# MCF5441x register map
Vendor: NXP; File version: 1.0
Registers are 32-bit, read-write, reset 0x0 unless marked. A register's access mark holds for its fields unless they carry their own. Offsets are from the block's base; [hi:lo] are bit positions; {n}, {i} and the like mark numbered series.

## ADC
Base 0xFC094000
0x00 CR1 16-bit reset 0x5005
0x02 CR2 16-bit reset 0x5080
0x04 ZCCR 16-bit
0x06 LST1 16-bit reset 0x3210
0x08 LST2 16-bit reset 0x7654
0x0A SDIS 16-bit
0x0C SR 16-bit
0x0E LSR 16-bit
0x10 ZCSR 16-bit
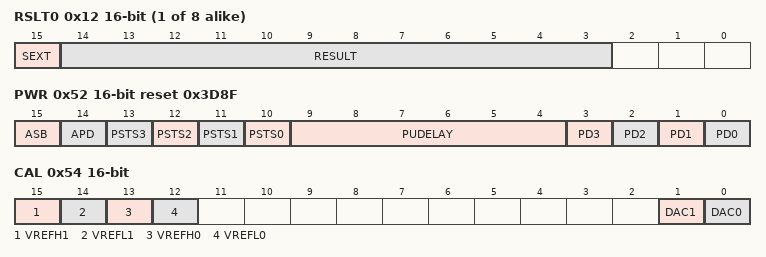
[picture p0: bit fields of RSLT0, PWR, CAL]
{0x12+2i} RSLT{i} 16-bit (i=0..7)
  [15] SEXT read-has-side-effects
    0=POSITIVE_RESULT; 1=NEGATIVE_RESULT
  [14:3] RESULT read-has-side-effects
{0x22+2i} LLMT{i} 16-bit (i=0..7)
{0x32+2i} HLMT{i} 16-bit reset 0x7FF8 (i=0..7)
{0x42+2i} OFS{i} 16-bit (i=0..7)
  [14:3] OFFSET
0x52 PWR 16-bit reset 0x3D8F
  [15] ASB
    0=DISABLED; 1=ENABLED
  [14] APD
  [n+10] PSTS{n} (n=0..3)
  [9:4] PUDELAY
  [n] PD{n} (n=0..3)
0x54 CAL 16-bit
  [15] VREFH1
    0=INTERNAL_VDDA; 1=ADC_IN4
  [14] VREFL1
    0=INTERNAL_VSSA; 1=ADC_IN5
  [13] VREFH0
    0=INTERNAL_VDDA; 1=ADC_IN0
  [12] VREFL0
    0=INTERNAL_VSSA; 1=ADC_IN1
  [1] DAC1
  [0] DAC0
0x56 PWR2 16-bit reset 0x5
0x58 DIV 16-bit reset 0x505
0x5A ASDIV 16-bit reset 0x137

## CCM
Base 0xEC090000
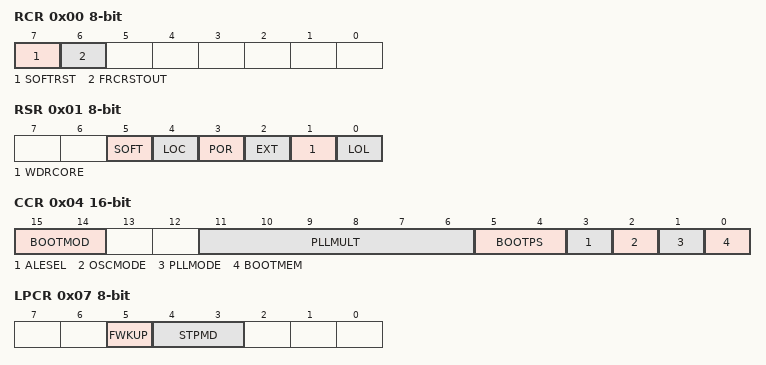
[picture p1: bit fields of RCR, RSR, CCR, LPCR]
0x00 RCR 8-bit
  [7] SOFTRST
    0=NO_SOFTWARE_RESET_REQUEST; 1=SOFTWARE_RESET_REQUEST
  [6] FRCRSTOUT
    0=NEGATE_RSTOUT; 1=ASSERT_RSTOUT
0x01 RSR 8-bit ro reset not defined
  [5] SOFT, [4] LOC, [3] POR, [2] EXT, [1] WDRCORE, [0] LOL
0x04 CCR 16-bit ro reset not defined
  [15:14] BOOTMOD
  [11:6] PLLMULT
  [5:4] BOOTPS
  [3] ALESEL
    0=TS; 1=ALE
  [2] OSCMODE
    0=CRYSTAL_OSCILLATOR_MODE; 1=OSCILLATOR_BYPASS_MODE
  [1] PLLMODE
    0=DISABLED; 1=ENABLED
  [0] BOOTMEM
    0=NAND_FLASH; 1=FLEXBUS
0x07 LPCR 8-bit
  [5] FWKUP, [4:3] STPMD
0x08 RCON 16-bit ro reset 0x1259
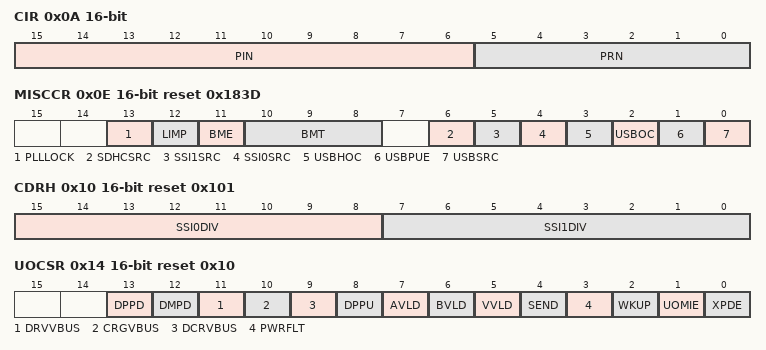
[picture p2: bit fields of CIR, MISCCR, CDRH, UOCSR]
0x0A CIR 16-bit ro reset not defined
  [15:6] PIN, [5:0] PRN
0x0E MISCCR 16-bit reset 0x183D
  [13] PLLLOCK
    0=NOT_LOCKED; 1=LOCKED
  [12] LIMP
  [11] BME
  [10:8] BMT
  [6] SDHCSRC
    0=OSCILLATOR_OUTPUT; 1=PLL_DIVIDER_OUTPUT
  [5] SSI1SRC
    0=SSI_CLKIN_PIN; 1=PLL_OUTPUT
  [4] SSI0SRC
    0=SSI_CLKIN_PIN; 1=PLL_OUTPUT
  [3] USBHOC
    0=LOW; 1=HIGH
  [2] USBOC
    0=LOW; 1=HIGH
  [1] USBPUE
  [0] USBSRC
0x10 CDRH 16-bit reset 0x101
  [15:8] SSI0DIV, [7:0] SSI1DIV
0x12 CDRL 16-bit
  [11:8] LPDIV
0x14 UOCSR 16-bit reset 0x10
  [13] DPPD read-has-side-effects
    0=DISABLED; 1=ENABLED
  [12] DMPD read-has-side-effects
    0=DISABLED; 1=ENABLED
  [11] DRVVBUS read-has-side-effects
  [10] CRGVBUS read-has-side-effects
  [9] DCRVBUS read-has-side-effects
  [8] DPPU read-has-side-effects
  [7] AVLD read-has-side-effects
  [6] BVLD read-has-side-effects
  [5] VVLD read-has-side-effects
  [4] SEND read-has-side-effects
  [3] PWRFLT read-has-side-effects
  [2] WKUP read-has-side-effects
  [1] UOMIE read-has-side-effects
    0=DISABLED; 1=ENABLED
  [0] XPDE read-has-side-effects
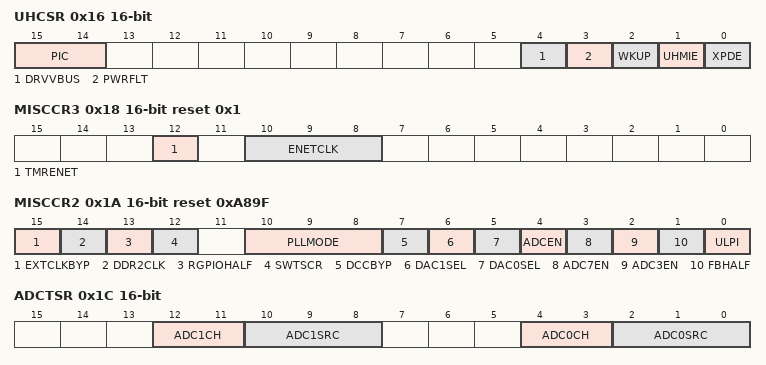
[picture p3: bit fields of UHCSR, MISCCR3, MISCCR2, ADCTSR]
0x16 UHCSR 16-bit
  [15:14] PIC read-has-side-effects
  [4] DRVVBUS read-has-side-effects
  [3] PWRFLT read-has-side-effects
  [2] WKUP read-has-side-effects
  [1] UHMIE read-has-side-effects
    0=DISABLED; 1=ENABLED
  [0] XPDE read-has-side-effects
0x18 MISCCR3 16-bit reset 0x1
  [12] TMRENET
    0=MAC0_1588_TIMEBASE_COUNTER; 1=MAC1_1588_TIMEBASE_COUNTER
  [10:8] ENETCLK
0x1A MISCCR2 16-bit reset 0xA89F
  [15] EXTCLKBYP
  [14] DDR2CLK
  [13] RGPIOHALF
  [12] SWTSCR
  [10:8] PLLMODE
  [7] DCCBYP
  [6] DAC1SEL
  [5] DAC0SEL
  [4] ADCEN
    0=DISABLED; 1=ENABLED
  [3] ADC7EN
    0=DISABLED; 1=ENABLED
  [2] ADC3EN
    0=DISABLED; 1=ENABLED
  [1] FBHALF
    0=FLEXBUS_RUNS_AT_FSYS_2; 1=FLEXBUS_RUNS_AT_FSYS_4
  [0] ULPI
0x1C ADCTSR 16-bit
  [12:11] ADC1CH, [10:8] ADC1SRC, [4:3] ADC0CH, [2:0] ADC0SRC
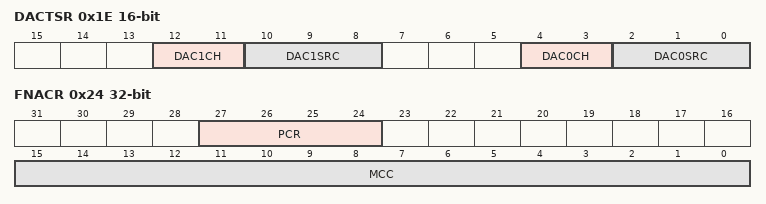
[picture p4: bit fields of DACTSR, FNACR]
0x1E DACTSR 16-bit
  [12:11] DAC1CH, [10:8] DAC1SRC, [4:3] DAC0CH, [2:0] DAC0SRC
0x20 SBFSR 16-bit ro reset not defined
  [15:0] BLL
0x22 SBFCR 16-bit reset not defined
  [4] FR
0x24 FNACR
  [27:24] PCR, [15:0] MCC

## PLL
Base 0xFC0C0000
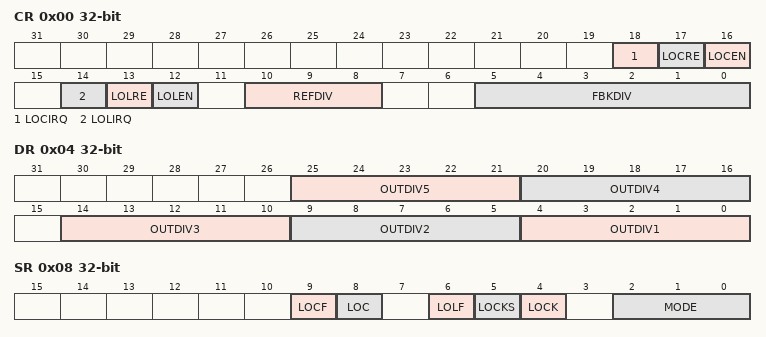
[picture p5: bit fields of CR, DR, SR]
0x00 CR reset not defined
  [18] LOCIRQ
  [17] LOCRE
  [16] LOCEN
    0=DISABLED; 1=ENABLED
  [14] LOLIRQ
  [13] LOLRE
  [12] LOLEN
    0=DISABLED; 1=ENABLED
  [10:8] REFDIV
  [5:0] FBKDIV
0x04 DR reset not defined
  [25:21] OUTDIV5, [20:16] OUTDIV4, [14:10] OUTDIV3, [9:5] OUTDIV2, [4:0] OUTDIV1
0x08 SR
  [9] LOCF
    0=NOT_REQUESTED; 1=REQUESTED
  [8] LOC
  [6] LOLF
    0=NOT_REQUESTED; 1=REQUESTED
  [5] LOCKS
  [4] LOCK
    0=UNLOCKED; 1=LOCKED
  [2:0] MODE
